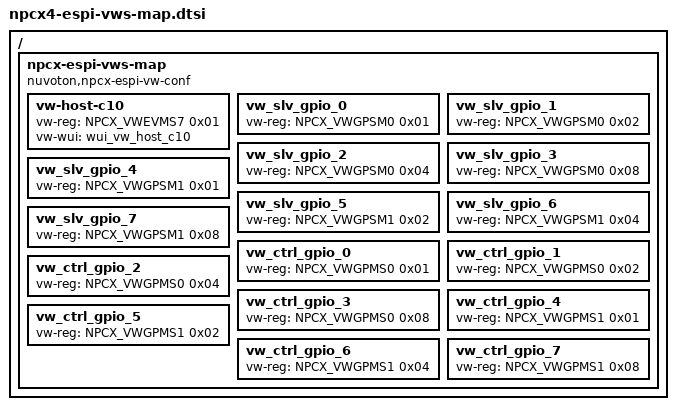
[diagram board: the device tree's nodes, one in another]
/*
 * Copyright (c) 2023 Nuvoton Technology Corporation.
 *
 * SPDX-License-Identifier: Apache-2.0
 */

/* Common eSPI Virtual Wire (VW) mapping configurations in npcx family */
#include <nuvoton/npcx/npcx-espi-vws-map.dtsi>

/*
 *   Specific eSPI Virtual Wire (VW) mapping configurations in npcx4 series
 * |--------------------------------------------------------------------------|
 * | VW idx | SLV reg | Wire Bit 3   | Wire Bit 2   | Wire Bit 1| Wire Bit 0  |
 * |--------------------------------------------------------------------------|
 * |                 Input (Master-to-Slave) Virtual Wires                    |
 * |--------------------------------------------------------------------------|
 * | 47h[P] | VWEVMS7 | Reserved     | Reserved     | Reserved  | HOST_C10    |
 * |--------------------------------------------------------------------------|
 * |                Output (Slave-to-Master) Virtual Wires                    |
 * |--------------------------------------------------------------------------|
 * |       Output (Slave-to-Master) Virtual Wires (High at reset state)       |
 * |--------------------------------------------------------------------------|
 * | 50h[P] | VWGPSM0 | SLV_GPIO_3   | SLV_GPIO_2   | SLV_GPIO_1| SLV_GPIO_0  |
 * | 51h[P] | VWGPSM1 | SLV_GPIO_7   | SLV_GPIO_6   | SLV_GPIO_5| SLV_GPIO_4  |
 * |--------------------------------------------------------------------------|
 *  [S] System-/[P] Platform-Specific Virtual Wires
 */

/ {
	npcx-espi-vws-map {
		compatible = "nuvoton,npcx-espi-vw-conf";

		/* eSPI Virtual Vire (VW) input configuration */
		/* index 47h (In) */
		vw-host-c10 {
			vw-reg = <NPCX_VWEVMS7 0x01>;
			vw-wui = <&wui_vw_host_c10>;
		};

		/*
		 * Virtual wires for platform level usage (High at Reset state)
		 */
		/* index 50h (Out) */
		vw_slv_gpio_0 {
			vw-reg = <NPCX_VWGPSM0 0x01>;
		};
		vw_slv_gpio_1 {
			vw-reg = <NPCX_VWGPSM0 0x02>;
		};
		vw_slv_gpio_2 {
			vw-reg = <NPCX_VWGPSM0 0x04>;
		};
		vw_slv_gpio_3 {
			vw-reg = <NPCX_VWGPSM0 0x08>;
		};

		/* index 51h (Out) */
		vw_slv_gpio_4 {
			vw-reg = <NPCX_VWGPSM1 0x01>;
		};
		vw_slv_gpio_5 {
			vw-reg = <NPCX_VWGPSM1 0x02>;
		};
		vw_slv_gpio_6 {
			vw-reg = <NPCX_VWGPSM1 0x04>;
		};
		vw_slv_gpio_7 {
			vw-reg = <NPCX_VWGPSM1 0x08>;
		};

		/*
		 * Virtual wires for platform level usage (High at Reset state)
		 */
		/* index 60h (In) */
		vw_ctrl_gpio_0 {
			vw-reg = <NPCX_VWGPMS0 0x01>;
		};
		vw_ctrl_gpio_1 {
			vw-reg = <NPCX_VWGPMS0 0x02>;
		};
		vw_ctrl_gpio_2 {
			vw-reg = <NPCX_VWGPMS0 0x04>;
		};
		vw_ctrl_gpio_3 {
			vw-reg = <NPCX_VWGPMS0 0x08>;
		};

		/* index 61h (In) */
		vw_ctrl_gpio_4 {
			vw-reg = <NPCX_VWGPMS1 0x01>;
		};
		vw_ctrl_gpio_5 {
			vw-reg = <NPCX_VWGPMS1 0x02>;
		};
		vw_ctrl_gpio_6 {
			vw-reg = <NPCX_VWGPMS1 0x04>;
		};
		vw_ctrl_gpio_7 {
			vw-reg = <NPCX_VWGPMS1 0x08>;
		};
	};
};
